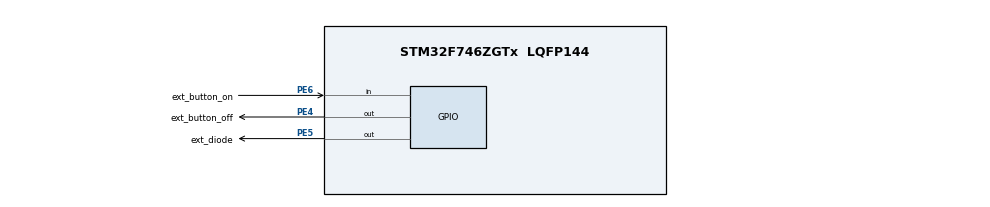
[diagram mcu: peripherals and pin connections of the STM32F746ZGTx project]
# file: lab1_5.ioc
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CORTEX_M7.default_mode_Activation=1
Mcu.Family=STM32F7
Mcu.Name=STM32F746ZGTx
Mcu.Package=LQFP144
NVIC.PriorityGroup=NVIC_PRIORITYGROUP_4
PE4.GPIO_Label=ext_button_off
PE4.Signal=GPIO_Output
PE5.GPIO_Label=ext_diode
PE5.Signal=GPIO_Output
PE6.GPIO_Label=ext_button_on
PE6.Signal=GPIO_Input
ProjectManager.HeapSize=0x200
ProjectManager.StackSize=0x400
ProjectManager.TargetToolchain=STM32CubeIDE
RCC.HSE_VALUE=25000000
RCC.HSI_VALUE=16000000
RCC.LSE_VALUE=32768
RCC.USBFreq_Value=96000000
RCC.VCOOutputFreq_Value=192000000
board=custom

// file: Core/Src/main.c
/* USER CODE BEGIN Header */
/**
  ******************************************************************************
  * @file           : main.c
  * @brief          : Main program body
  ******************************************************************************
  * @attention
  *
  * Copyright (c) 2025 STMicroelectronics.
  * All rights reserved.
  *
  * This software is licensed under terms that can be found in the LICENSE file
  * in the root directory of this software component.
  * If no LICENSE file comes with this software, it is provided AS-IS.
  *
  ******************************************************************************
  */
/* USER CODE END Header */
#include "main.h"

/* USER CODE BEGIN Includes */
#include <stdbool.h>
/* USER CODE END Includes */

void SystemClock_Config(void);
static void MPU_Config(void);
static void MX_GPIO_Init(void);

int main(void)
{

  /* MPU Configuration--------------------------------------------------------*/
  MPU_Config();

  /* MCU Configuration--------------------------------------------------------*/

  /* Reset of all peripherals, Initializes the Flash interface and the Systick. */
  HAL_Init();

  /* Configure the system clock */
  SystemClock_Config();

  /* Initialize all configured peripherals */
  MX_GPIO_Init();
  /* USER CODE BEGIN 2 */

  	  typedef struct{
    	 GPIO_TypeDef* port;
    	 uint16_t pin;
      }pin_t;

      typedef struct{
    	  pin_t gpio;
    	  uint8_t prev_state;
    	  uint8_t pressed;
      }Button;

      Button buttonON = {{ext_button_on_GPIO_Port, ext_button_on_Pin}, 0, 0}; // Changed
      Button buttonOFF = {{ext_button_off_GPIO_Port, ext_button_off_Pin}, 0, 0}; // Added
      pin_t LED1 = {ext_diode_GPIO_Port, ext_diode_Pin};

      bool key_pooling(Button* btn, bool normal_open) // Changed
      {
            uint8_t curr_state = HAL_GPIO_ReadPin(btn->gpio.port, btn->gpio.pin);

            if (btn->prev_state == !normal_open && curr_state == normal_open)
            {
                btn->pressed = normal_open;
                btn->prev_state = curr_state;
                return true;
            }

            btn->prev_state = curr_state;
            btn->pressed = !normal_open;
            return false;
     }

     void handle_led_buttons(Button* btn_on,  bool btn_on_normal_open, Button* btn_off, bool btn_off_normal_open, pin_t led) // Added
     {
    	 if(key_pooling(btn_on, btn_on_normal_open))
    	 {
    		 HAL_GPIO_WritePin(led.port, led.pin, GPIO_PIN_SET);
    	 }
    	 if(key_pooling(btn_off, btn_off_normal_open))
    	 {
    		 HAL_GPIO_WritePin(led.port, led.pin, GPIO_PIN_RESET);
    	 }
     }
  /* USER CODE END 2 */

  /* Infinite loop */
  /* USER CODE BEGIN WHILE */
  while (1)
  {
	  handle_led_buttons(&buttonON, false, &buttonOFF, true, LED1);
	  HAL_Delay(0);
    /* USER CODE END WHILE */

  }
}

void SystemClock_Config(void)
{
  RCC_OscInitTypeDef RCC_OscInitStruct = {0};
  RCC_ClkInitTypeDef RCC_ClkInitStruct = {0};

  /** Configure the main internal regulator output voltage
  */
  __HAL_RCC_PWR_CLK_ENABLE();
  __HAL_PWR_VOLTAGESCALING_CONFIG(PWR_REGULATOR_VOLTAGE_SCALE3);

  /** Initializes the RCC Oscillators according to the specified parameters
  * in the RCC_OscInitTypeDef structure.
  */
  RCC_OscInitStruct.OscillatorType = RCC_OSCILLATORTYPE_HSI;
  RCC_OscInitStruct.HSIState = RCC_HSI_ON;
  RCC_OscInitStruct.HSICalibrationValue = RCC_HSICALIBRATION_DEFAULT;
  RCC_OscInitStruct.PLL.PLLState = RCC_PLL_NONE;
  if (HAL_RCC_OscConfig(&RCC_OscInitStruct) != HAL_OK)
  {
    Error_Handler();
  }

  /** Initializes the CPU, AHB and APB buses clocks
  */
  RCC_ClkInitStruct.ClockType = RCC_CLOCKTYPE_HCLK|RCC_CLOCKTYPE_SYSCLK
                              |RCC_CLOCKTYPE_PCLK1|RCC_CLOCKTYPE_PCLK2;
  RCC_ClkInitStruct.SYSCLKSource = RCC_SYSCLKSOURCE_HSI;
  RCC_ClkInitStruct.AHBCLKDivider = RCC_SYSCLK_DIV1;
  RCC_ClkInitStruct.APB1CLKDivider = RCC_HCLK_DIV1;
  RCC_ClkInitStruct.APB2CLKDivider = RCC_HCLK_DIV1;

  if (HAL_RCC_ClockConfig(&RCC_ClkInitStruct, FLASH_LATENCY_0) != HAL_OK)
  {
    Error_Handler();
  }
}

static void MX_GPIO_Init(void)
{
  GPIO_InitTypeDef GPIO_InitStruct = {0};

  /* GPIO Ports Clock Enable */
  __HAL_RCC_GPIOE_CLK_ENABLE();

  /*Configure GPIO pin Output Level */
  HAL_GPIO_WritePin(GPIOE, ext_button_off_Pin|ext_diode_Pin, GPIO_PIN_RESET);

  /*Configure GPIO pins : ext_button_off_Pin ext_diode_Pin */
  GPIO_InitStruct.Pin = ext_button_off_Pin|ext_diode_Pin;
  GPIO_InitStruct.Mode = GPIO_MODE_OUTPUT_PP;
  GPIO_InitStruct.Pull = GPIO_NOPULL;
  GPIO_InitStruct.Speed = GPIO_SPEED_FREQ_LOW;
  HAL_GPIO_Init(GPIOE, &GPIO_InitStruct);

  /*Configure GPIO pin : ext_button_on_Pin */
  GPIO_InitStruct.Pin = ext_button_on_Pin;
  GPIO_InitStruct.Mode = GPIO_MODE_INPUT;
  GPIO_InitStruct.Pull = GPIO_NOPULL;
  HAL_GPIO_Init(ext_button_on_GPIO_Port, &GPIO_InitStruct);

}

 /* MPU Configuration */

void MPU_Config(void)
{
  MPU_Region_InitTypeDef MPU_InitStruct = {0};

  /* Disables the MPU */
  HAL_MPU_Disable();

  /** Initializes and configures the Region and the memory to be protected
  */
  MPU_InitStruct.Enable = MPU_REGION_ENABLE;
  MPU_InitStruct.Number = MPU_REGION_NUMBER0;
  MPU_InitStruct.BaseAddress = 0x0;
  MPU_InitStruct.Size = MPU_REGION_SIZE_4GB;
  MPU_InitStruct.SubRegionDisable = 0x87;
  MPU_InitStruct.TypeExtField = MPU_TEX_LEVEL0;
  MPU_InitStruct.AccessPermission = MPU_REGION_NO_ACCESS;
  MPU_InitStruct.DisableExec = MPU_INSTRUCTION_ACCESS_DISABLE;
  MPU_InitStruct.IsShareable = MPU_ACCESS_SHAREABLE;
  MPU_InitStruct.IsCacheable = MPU_ACCESS_NOT_CACHEABLE;
  MPU_InitStruct.IsBufferable = MPU_ACCESS_NOT_BUFFERABLE;

  HAL_MPU_ConfigRegion(&MPU_InitStruct);
  /* Enables the MPU */
  HAL_MPU_Enable(MPU_PRIVILEGED_DEFAULT);

}

void Error_Handler(void)
{
  __disable_irq();
  while (1)
  {
  }
}
